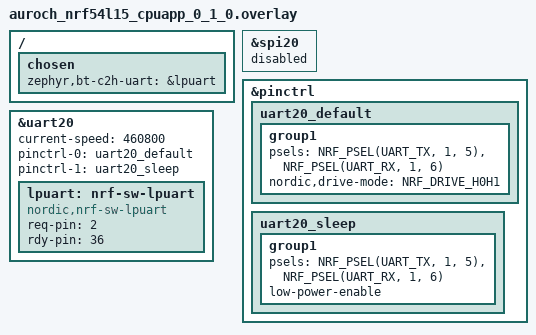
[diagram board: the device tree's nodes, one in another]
/* Use LPUART for HCI link instead of SPI due to nRF54L15 pin issues */

/delete-node/ &hci_spi;

&spi20 {
	status = "disabled";
};

/ {
	chosen {
		zephyr,bt-c2h-uart=&lpuart;
	};
};

&pinctrl {
	uart20_default: uart20_default {
		group1 {
			psels = <NRF_PSEL(UART_TX, 1, 5)>,
				<NRF_PSEL(UART_RX, 1, 6)>;
			nordic,drive-mode = <NRF_DRIVE_H0H1>;
		};
	};

	uart20_sleep: uart20_sleep {
		group1 {
			psels = <NRF_PSEL(UART_TX, 1, 5)>,
				<NRF_PSEL(UART_RX, 1, 6)>;
			low-power-enable;
		};
	};
};

&uart20 {
	current-speed = <460800>;
	status = "okay";
	pinctrl-0 = <&uart20_default>;
	pinctrl-1 = <&uart20_sleep>;
	pinctrl-names = "default", "sleep";

	lpuart: nrf-sw-lpuart {
		compatible = "nordic,nrf-sw-lpuart";
		status = "okay";
		req-pin = <2>;
		rdy-pin = <36>;
	};
};
